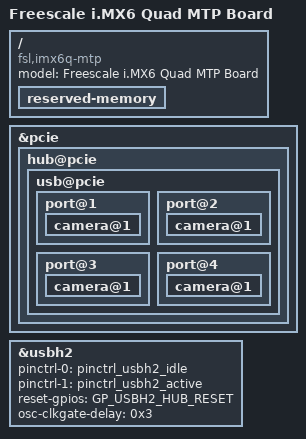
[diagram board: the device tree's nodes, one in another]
/*
 * Copyright 2013 Boundary Devices
 * Copyright 2012 Freescale Semiconductor, Inc.
 * Copyright 2011 Linaro Ltd.
 *
 * The code contained herein is licensed under the GNU General Public
 * License. You may obtain a copy of the GNU General Public License
 * Version 2 or later at the following locations:
 *
 * http://www.opensource.org/licenses/gpl-license.html
 * http://www.gnu.org/copyleft/gpl.html
 */

/dts-v1/;

#include <dt-bindings/interrupt-controller/irq.h>
#include "imx6q.dtsi"
#include "imx6qdl-mtp.dtsi"

/ {
	model = "Freescale i.MX6 Quad MTP Board";
	compatible = "fsl,imx6q-mtp", "fsl,imx6q";
};

/ {
	reserved-memory {
		/delete-node/ camera-reserved;
	};
};

&pcie {
	hub@pcie {
		usb@pcie {
			port@1 {
				/delete-property/ memory-region;
				camera@1 {
					/delete-property/ memory-region;
				};
			};

			port@2 {
				/delete-property/ memory-region;
				camera@1 {
					/delete-property/ memory-region;
				};
			};

			port@3 {
				/delete-property/ memory-region;
				camera@1 {
					/delete-property/ memory-region;
				};
			};

			port@4 {
				/delete-property/ memory-region;
				camera@1 {
					/delete-property/ memory-region;
				};
			};
		};
	};
};

&usbh2 {
	pinctrl-names = "idle", "active";
	pinctrl-0 = <&pinctrl_usbh2_idle>;
	pinctrl-1 = <&pinctrl_usbh2_active>;
	reset-gpios = GP_USBH2_HUB_RESET;
	osc-clkgate-delay = <0x3>;
	status = "okay";
};
